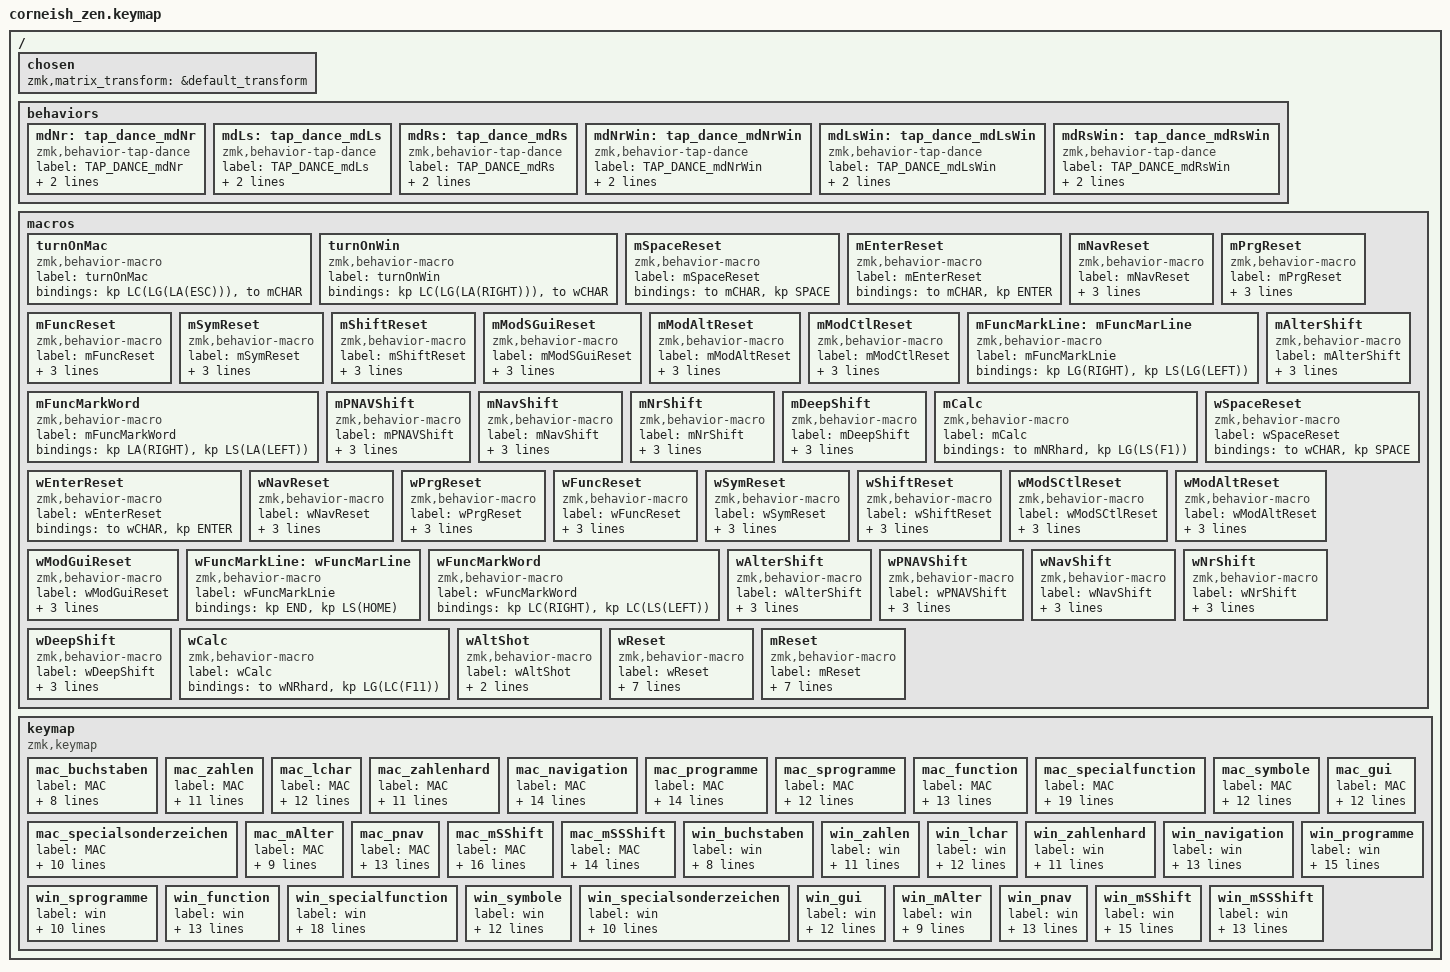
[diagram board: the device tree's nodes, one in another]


#include <behaviors.dtsi>
#include <dt-bindings/zmk/keys.h>
#include <dt-bindings/zmk/bt.h>


// ------- MAC -------------------

#define mCHAR 0
#define mNR 1
#define mLCHAR 2
#define mNRhard 3

#define mNAV 4

#define mPRG 5
#define mSPRG 6

#define mFUNC 7
#define mSFUNC 8

#define mSYM 9
#define mSSYM 10

#define mGUI 11

#define mAlter 12
#define mPNAV 13

#define mSShift 14
#define mSSShift 15


// ------- WIN -------------------


#define wCHAR 16
#define wNR 17
#define wLCHAR 18
#define wNRhard 19

#define wNAV 20

#define wPRG 21
#define wSPRG 22

#define wFUNC 23
#define wSFUNC 24

#define wSYM 25
#define wSSYM 26

#define wGUI 27

#define wAlter 28
#define wPNAV 29

#define wSShift 30
#define wSSShift 31




/ {
    chosen {
    	zmk,matrix_transform = &default_transform;
    };
};




/ {

    behaviors {

	

		// ------------------------- MAC ---------------------
	

        mdNr: tap_dance_mdNr {
            compatible = "zmk,behavior-tap-dance";
            label = "TAP_DANCE_mdNr";
            #binding-cells = <0>;
            tapping-term-ms = <200>;
            bindings = <&to mNR>, <&to mNRhard>;
        };


		mdLs: tap_dance_mdLs {
            compatible = "zmk,behavior-tap-dance";
            label = "TAP_DANCE_mdLs";
            #binding-cells = <0>;
            tapping-term-ms = <1000>;
            bindings = <&sl mLCHAR>, <&to mLCHAR>;
        };
		mdRs: tap_dance_mdRs {
            compatible = "zmk,behavior-tap-dance";
            label = "TAP_DANCE_mdRs";
            #binding-cells = <0>;
            tapping-term-ms = <1000>;
            bindings = <&sl mLCHAR>, <&to mLCHAR>;
        };



		// ------------------------- WiN ---------------------

		mdNrWin: tap_dance_mdNrWin {
            compatible = "zmk,behavior-tap-dance";
            label = "TAP_DANCE_mdNrWin";
            #binding-cells = <0>;
            tapping-term-ms = <200>;
            bindings = <&to wNR>, <&to wNRhard>;
        };

		mdLsWin: tap_dance_mdLsWin {
            compatible = "zmk,behavior-tap-dance";
            label = "TAP_DANCE_mdLsWin";
            #binding-cells = <0>;
            tapping-term-ms = <1000>;
            bindings = <&sl wLCHAR>, <&to wLCHAR>;
        };
		mdRsWin: tap_dance_mdRsWin {
            compatible = "zmk,behavior-tap-dance";
            label = "TAP_DANCE_mdRsWin";
            #binding-cells = <0>;
            tapping-term-ms = <1000>;
            bindings = <&sl wLCHAR>, <&to wLCHAR>;
        };

    };

	
	 macros {

		// OS Switch

		turnOnMac: turnOnMac {
            label = "turnOnMac";
            compatible = "zmk,behavior-macro";
            #binding-cells = <0>;
            bindings
                = <&kp LC(LG(LA(ESC)))>
				, <&to mCHAR>
                ;
    	};

		turnOnWin: turnOnWin {
            label = "turnOnWin";
            compatible = "zmk,behavior-macro";
            #binding-cells = <0>;
            bindings
                = <&kp LC(LG(LA(RIGHT)))>
                , <&to wCHAR>
                ;
    	};



		
		// ------------------------- MAC ---------------------

        mSpaceReset: mSpaceReset {
            label = "mSpaceReset";
            compatible = "zmk,behavior-macro";
            #binding-cells = <0>;
            bindings
                = <&to mCHAR>
                , <&kp SPACE>
                ;
    	};
		mEnterReset: mEnterReset {
            label = "mEnterReset";
            compatible = "zmk,behavior-macro";
            #binding-cells = <0>;
            bindings
                = <&to mCHAR>
                , <&kp ENTER>
                ;
    	};
		mNavReset: mNavReset {
            label = "mNavReset";
            compatible = "zmk,behavior-macro";
            #binding-cells = <0>;
            bindings
                = <&to mCHAR>
                , <&macro_press &sl mNAV>
    			, <&macro_pause_for_release>
				, <&macro_release &sl mNAV>
                ;
    	};
		mPrgReset: mPrgReset {
            label = "mPrgReset";
            compatible = "zmk,behavior-macro";
            #binding-cells = <0>;
            bindings
                = <&to mCHAR>
                , <&macro_press &sl mPRG>
    			, <&macro_pause_for_release>
				, <&macro_release &sl mPRG>
                ;
    	};
		mFuncReset: mFuncReset {
            label = "mFuncReset";
            compatible = "zmk,behavior-macro";
            #binding-cells = <0>;
            bindings
                = <&to mCHAR>
                , <&macro_press &sl mFUNC>
    			, <&macro_pause_for_release>
				, <&macro_release &sl mFUNC>
                ;
    	};
		mSymReset: mSymReset {
            label = "mSymReset";
            compatible = "zmk,behavior-macro";
            #binding-cells = <0>;
            bindings
                = <&to mCHAR>
                , <&macro_press &sl mSYM>
    			, <&macro_pause_for_release>
				, <&macro_release &sl mSYM>
                ;
    	};

		mShiftReset: mShiftReset {
            label = "mShiftReset";
            compatible = "zmk,behavior-macro";
            #binding-cells = <0>;
            bindings
                = <&to mCHAR>
                , <&macro_press &sl mLCHAR>
    			, <&macro_pause_for_release>
				, <&macro_release &sl mLCHAR>
                ;
    	};


		mModSGuiReset: mModSGuiReset {
            label = "mModSGuiReset";
            compatible = "zmk,behavior-macro";
            #binding-cells = <0>;
            bindings
                = <&to mCHAR>
                , <&macro_press &sk LS(LGUI)>
    			, <&macro_pause_for_release>
				, <&macro_release &sk LS(LGUI)>
                ;
    	};


		mModAltReset: mModAltReset {
            label = "mModAltReset";
            compatible = "zmk,behavior-macro";
            #binding-cells = <0>;
            bindings
                = <&to mCHAR>
                , <&macro_press &sk LALT>
    			, <&macro_pause_for_release>
				, <&macro_release &sk LALT>
                ;
    	};

		mModCtlReset: mModCtlReset {
            label = "mModCtlReset";
            compatible = "zmk,behavior-macro";
            #binding-cells = <0>;
            bindings
                = <&to mCHAR>
                , <&macro_press &sk LCTL>
    			, <&macro_pause_for_release>
				, <&macro_release &sk LCTL>
                ;
    	};





		mFuncMarkLine: mFuncMarLine {
            label = "mFuncMarkLnie";
            compatible = "zmk,behavior-macro";
            #binding-cells = <0>;
            bindings
                = <&kp LG(RIGHT)>
				, <&kp LS(LG(LEFT))>
                ;
    	};

		mFuncMarkWord: mFuncMarkWord {
            label = "mFuncMarkWord";
            compatible = "zmk,behavior-macro";
            #binding-cells = <0>;
            bindings
                = <&kp LA(RIGHT)>
				, <&kp LS(LA(LEFT))>
                ;
    	};



		mAlterShift: mAlterShift {
            label = "mAlterShift";
            compatible = "zmk,behavior-macro";
            #binding-cells = <0>;
            bindings
                = <&to mCHAR>
                , <&macro_press &sl mAlter>
    			, <&macro_pause_for_release>
				, <&macro_release &sl mAlter>
                ;
    	};

		mPNAVShift: mPNAVShift {
            label = "mPNAVShift";
            compatible = "zmk,behavior-macro";
            #binding-cells = <0>;
            bindings
                = <&to mCHAR>
                , <&macro_press &sl mPNAV>
    			, <&macro_pause_for_release>
				, <&macro_release &sl mPNAV>
                ;
    	};

		mNavShift: mNavShift {
            label = "mNavShift";
            compatible = "zmk,behavior-macro";
            #binding-cells = <0>;
            bindings
                = <&to mCHAR>
                , <&macro_press &sl mNAV>
    			, <&macro_pause_for_release>
				, <&macro_release &sl mNAV>
				;
    	};

		mNrShift: mNrShift {
            label = "mNrShift";
            compatible = "zmk,behavior-macro";
            #binding-cells = <0>;
            bindings
                = <&to mCHAR>
                , <&macro_press &sl mNR>
    			, <&macro_pause_for_release>
				, <&macro_release &sl mNR>
				;
    	};

		mDeepShift: mDeepShift {
            label = "mDeepShift";
            compatible = "zmk,behavior-macro";
            #binding-cells = <0>;
            bindings
                = <&to mCHAR>
                , <&macro_press &sl mPNAV>
    			, <&macro_pause_for_release>
				, <&macro_release &sl mPNAV>
				;
    	};

		mCalc: mCalc {
            label = "mCalc";
            compatible = "zmk,behavior-macro";
            #binding-cells = <0>;
            bindings
                = <&to mNRhard>
            	, <&kp LG(LS(F1))>
                ;
    	};





		// ------------------------- WiN ---------------------

        wSpaceReset: wSpaceReset {
            label = "wSpaceReset";
            compatible = "zmk,behavior-macro";
            #binding-cells = <0>;
            bindings
                = <&to wCHAR>
                , <&kp SPACE>
                ;
    	};
		wEnterReset: wEnterReset {
            label = "wEnterReset";
            compatible = "zmk,behavior-macro";
            #binding-cells = <0>;
            bindings
                = <&to wCHAR>
                , <&kp ENTER>
                ;
    	};
		wNavReset: wNavReset {
            label = "wNavReset";
            compatible = "zmk,behavior-macro";
            #binding-cells = <0>;
            bindings
                = <&to wCHAR>
                , <&macro_press &sl wNAV>
    			, <&macro_pause_for_release>
				, <&macro_release &sl wNAV>
                ;
    	};
		wPrgReset: wPrgReset {
            label = "wPrgReset";
            compatible = "zmk,behavior-macro";
            #binding-cells = <0>;
            bindings
                = <&to wCHAR>
                , <&macro_press &sl wPRG>
    			, <&macro_pause_for_release>
				, <&macro_release &sl wPRG>
                ;
    	};
		wFuncReset: wFuncReset {
            label = "wFuncReset";
            compatible = "zmk,behavior-macro";
            #binding-cells = <0>;
            bindings
                = <&to wCHAR>
                , <&macro_press &sl wFUNC>
    			, <&macro_pause_for_release>
				, <&macro_release &sl wFUNC>
                ;
    	};
		wSymReset: wSymReset {
            label = "wSymReset";
            compatible = "zmk,behavior-macro";
            #binding-cells = <0>;
            bindings
                = <&to wCHAR>
                , <&macro_press &sl wSYM>
    			, <&macro_pause_for_release>
				, <&macro_release &sl wSYM>
                ;
    	};

		wShiftReset: wShiftReset {
            label = "wShiftReset";
            compatible = "zmk,behavior-macro";
            #binding-cells = <0>;
            bindings
                = <&to wCHAR>
                , <&macro_press &sl wLCHAR>
    			, <&macro_pause_for_release>
				, <&macro_release &sl wLCHAR>
                ;
    	};



		wModSCtlReset: wModSCtlReset {
            label = "wModSCtlReset";
            compatible = "zmk,behavior-macro";
            #binding-cells = <0>;
            bindings
                = <&to wCHAR>
                , <&macro_press &sk LS(LCTL)>
    			, <&macro_pause_for_release>
				, <&macro_release &sk LS(LCTL)>
                ;
    	};


		wModAltReset: wModAltReset {
            label = "wModAltReset";
            compatible = "zmk,behavior-macro";
            #binding-cells = <0>;
            bindings
                = <&to wCHAR>
                , <&macro_press &sk LALT>
    			, <&macro_pause_for_release>
				, <&macro_release &sk LALT>
                ;
    	};

		wModGuiReset: wModGuiReset {
            label = "wModGuiReset";
            compatible = "zmk,behavior-macro";
            #binding-cells = <0>;
            bindings
                = <&to wCHAR>
                , <&macro_press &sk LGUI>
    			, <&macro_pause_for_release>
				, <&macro_release &sk LGUI>
                ;
    	};



		wFuncMarkLine: wFuncMarLine {
            label = "wFuncMarkLnie";
            compatible = "zmk,behavior-macro";
            #binding-cells = <0>;
            bindings
                = <&kp END>
				, <&kp LS(HOME)>
                ;
    	};

		wFuncMarkWord: wFuncMarkWord {
            label = "wFuncMarkWord";
            compatible = "zmk,behavior-macro";
            #binding-cells = <0>;
            bindings
                = <&kp LC(RIGHT)>
				, <&kp LC(LS(LEFT))>
                ;
    	};



		wAlterShift: wAlterShift {
            label = "wAlterShift";
            compatible = "zmk,behavior-macro";
            #binding-cells = <0>;
            bindings
                = <&to wCHAR>
                , <&macro_press &sl wAlter>
    			, <&macro_pause_for_release>
				, <&macro_release &sl wAlter>
                ;
    	};

		wPNAVShift: wPNAVShift {
            label = "wPNAVShift";
            compatible = "zmk,behavior-macro";
            #binding-cells = <0>;
            bindings
                = <&to wCHAR>
                , <&macro_press &sl wPNAV>
    			, <&macro_pause_for_release>
				, <&macro_release &sl wPNAV>
                ;
    	};

		wNavShift: wNavShift {
            label = "wNavShift";
            compatible = "zmk,behavior-macro";
            #binding-cells = <0>;
            bindings
                = <&to wCHAR>
                , <&macro_press &sl wNAV>
    			, <&macro_pause_for_release>
				, <&macro_release &sl wNAV>
				;
    	};


		wNrShift: wNrShift {
            label = "wNrShift";
            compatible = "zmk,behavior-macro";
            #binding-cells = <0>;
            bindings
                = <&to wCHAR>
                , <&macro_press &sl wNR>
    			, <&macro_pause_for_release>
				, <&macro_release &sl wNR>
				;
    	};

		wDeepShift: wDeepShift {
            label = "wDeepShift";
            compatible = "zmk,behavior-macro";
            #binding-cells = <0>;
            bindings
                = <&to wCHAR>
                , <&macro_press &sl wPNAV>
    			, <&macro_pause_for_release>
				, <&macro_release &sl wPNAV>
				;
    	};

		wCalc: wCalc {
            label = "wCalc";
            compatible = "zmk,behavior-macro";
            #binding-cells = <0>;
            bindings
                = <&to wNRhard>
            	, <&kp LG(LC(F11))>
                ;
    	};

		wAltShot: wAltShot {
            label = "wAltShot";
            compatible = "zmk,behavior-macro";
            #binding-cells = <0>;
            bindings
                = <&macro_press &kp LALT>
				, <&macro_release  &kp LALT>
                ;
    	};


		// Reset

		wReset: wReset {
            label = "wReset";
            compatible = "zmk,behavior-macro";
            #binding-cells = <0>;
            bindings
				= <&to wCHAR>
				, <&kp LC(LG(LA(NUBS)))>
				, <&macro_release &kp LALT>
				, <&macro_release &kp RALT>
				, <&macro_release &kp LCTL>
				, <&macro_release &kp RCTL>
				, <&macro_release &kp LSFT>
				, <&macro_release &kp RSFT>
				, <&macro_release &kp LGUI>
				, <&macro_release &kp RGUI>

                ; 
    	};

		mReset: mReset {
            label = "mReset";
            compatible = "zmk,behavior-macro";
            #binding-cells = <0>;
            bindings
				= <&to mCHAR>
				, <&kp LC(LG(LA(NUBS)))>
				, <&macro_release &kp LALT>
				, <&macro_release &kp RALT>
				, <&macro_release &kp LCTL>
				, <&macro_release &kp RCTL>
				, <&macro_release &kp LSFT>
				, <&macro_release &kp RSFT>
				, <&macro_release &kp LGUI>
				, <&macro_release &kp RGUI>
                ; 
    	};




	};





	keymap
	{	
		compatible = "zmk,keymap";



		// ----------------------------------------------------------------------------------------------|
		// 											MAC			
		// ----------------------------------------------------------------------------------------------|


		// -----------------------------------------------------|
		// Layer 0 - mChar = 	  Buchstaben					|
		// -----------------------------------------------------|
	
		mac_buchstaben
		{
			label = "MAC";

			bindings = <

				// ----------------------------------------

				&kp ESC
				&kp J 
				&kp D	 
				&kp U
				&kp A
				&kp X

				&kp P
				&kp H
				&kp L
				&kp M
				&kp W
				&kp BSPC

				// ----------------------------------------
	
				&sl mSShift
				&kp C
				&kp T
				&kp I
				&kp E
				&kp O

				&kp B
				&kp N
				&kp R
				&kp S
				&kp G
				&kp RET

				// ----------------------------------------
	
				&mdLs
				&kp F
				&kp V
				&kp MINUS
				&kp Y
				&kp Q

				&kp Z
				&kp SEMI
				&kp LBKT
				&kp SQT
				&kp K
				&mdRs

				// ----------------------------------------

				&sl mSYM
				&kp SPACE
				&sl mFUNC
				&sl mPRG
				&sl mNAV
				&mdNr

				// ----------------------------------------
			>;
		};



		// -----------------------------------------------------|
		// Layer 1 - mNR = 	  Zahlen 							|
		// -----------------------------------------------------|

		mac_zahlen
		{
			label = "MAC";

			bindings = <

				// ----------------------------------------

				&kp ESC	
				&kp RBKT  				// +
				&kp NUBS				// Spitze
				&kp LS(NUBS)			// Spitze
				&kp GRAVE				// ^
				&kp X
				
				&kp LS(NUHS)			// '
				&kp LS(DOT)				// :
				&kp LS(COMMA)			// ;
				&kp M
				&kp LS(RBKT)			// *				
				&kp BACKSPACE

				// ----------------------------------------

				&sl mSShift
				&kp N1				
				&kp N2				
				&kp N3				
				&kp N4					
				&kp N5		

				&kp N6				
				&kp N7				
				&kp N8			
				&kp N9				
				&kp N0				
				&mEnterReset 

				// ----------------------------------------

				&mShiftReset
				&kp LS(N7)				// /
				&kp LS(LA(N7))			// backlslash
				&kp LS(N5)				// %
				&kp LA(E)				// €
				&kp GRAVE				// ^

				&kp LS(N0)				// =
				&kp DOT					// .
				&kp COMMA				// ,
				&kp LS(SLASH)			// _
				&kp SLASH 				// -
				&mShiftReset

				// ----------------------------------------
		
				&mSymReset
				&mSpaceReset 
				&mFuncReset
				&mPrgReset
				&mNavReset
				&none
			>;		
		};



		// -----------------------------------------------------|
		// Layer 2 - mLCHAR = 	  Buchstaben Lock				|
		// -----------------------------------------------------|
	
		mac_lchar
		{
			label = "MAC";

			bindings = <

				// ----------------------------------------

				&kp ESC
				&kp LS(J) 
				&kp LS(D)	 
				&kp LS(U)
				&kp LS(A)
				&kp LS(X)

				&kp LS(P)
				&kp LS(H)
				&kp LS(L)
				&kp LS(M)
				&kp LS(W)
				&kp LS(BSPC)

				// ----------------------------------------
	
				&sl mSShift
				&kp LS(C)
				&kp LS(T)
				&kp LS(I)
				&kp LS(E)
				&kp LS(O)
			
				&kp LS(B)
				&kp LS(N)
				&kp LS(R)
				&kp LS(S)
				&kp LS(G)
				&mEnterReset

				// ----------------------------------------

				&mShiftReset
				&kp LS(F)
				&kp LS(V)
				&kp LS(MINUS)
				&kp LS(Y)
				&kp LS(Q)

				&kp LS(Z)
				&kp LS(SEMI)
				&kp LS(LBKT)
				&kp LS(SQT)
				&kp LS(K)
				&mShiftReset						

				// ----------------------------------------

				&sl mSYM
				&mSpaceReset 
				&mFuncReset
				&mPrgReset
				&mNavReset
				&mdNr

				// ----------------------------------------
			>;
		};



		// -----------------------------------------------------|
		// Layer 3 - mNRhard = 	  Zahlen Hard Lock				|
		// -----------------------------------------------------|

		mac_zahlenhard
		{
			label = "MAC";

			bindings = <

				// ----------------------------------------

				&kp ESC	
				&kp RBKT  				// +
				&kp NUBS				// Spitze
				&kp LS(NUBS)			// Spitze
				&kp GRAVE				// ^
				&kp X
				
				&kp LS(NUHS)			// '
				&kp LS(DOT)				// :
				&kp LS(COMMA)			// ;
				&kp M
				&kp LS(RBKT)			// *	
				&kp BSPC

				// ----------------------------------------

				&sl mSShift
				&kp N1				
				&kp N2				
				&kp N3				
				&kp N4					
				&kp N5		

				&kp N6				
				&kp N7				
				&kp N8				
				&kp N9				
				&kp N0				
				&kp ENTER 

				// ----------------------------------------

				&mShiftReset
				&kp LS(N7)				// /
				&kp LS(LA(N7))			// backlslash
				&kp LS(N5)				// %
				&kp LA(E)				// €
				&kp GRAVE				// ^

				&kp LS(N0)				// =
				&kp DOT					// .
				&kp COMMA				// ,
				&kp LS(SLASH)			// _
				&kp SLASH 				// -
				&mShiftReset

				// ----------------------------------------
		
				&sl mSYM
				&kp SPACE
				&sl mFUNC
				&sl mPRG
				&sl mNAV
				&mdNr
			>;		
		};





		// -----------------------------------------------------|
		// Layer = 4 - mNAV - Navigation						|
		// -----------------------------------------------------|

		mac_navigation
		{		
			label = "MAC";

			bindings = <

				// ----------------------------------------

				&kp ESC						// -
				&kp LG(UP)					// @Home Sprung
				&kp LS(TAB)
				&kp UP						// @Up
				&kp TAB
				&kp LG(LA(F16))	
		
				&kp LG(LA(F17))				 
				&kp LC(GRAVE)			
				&kp PG_UP
				&kp LC(EQUAL)
				&kp LG(LS(UP))			
				&kp DEL					// -

				// ----------------------------------------

				&kp LC(COMMA)				 	// 
				&kp LG(DOWN)				// @End Sprung
				&kp LEFT 					// @Left
				&kp DOWN					// @Down
				&kp RIGHT 					// @Right
				&kp LC(DOT)			 	// 

				&kp LC(LS(F10))		
				&kp LS(LC(TAB))				 
				&kp PG_DN
				&kp LC(TAB)				 	
				&kp LG(LS(DOWN))	
				&kp ENTER					
				
				// ----------------------------------------

				&kp LCTRL
				&kp LG(LEFT)				// @Home 
				&kp LA(LEFT)				// @Wort Sprung
				&kp LA(RIGHT)				// @Wort Sprung
				&kp LG(RIGHT)				// @End  
				&kp LG(LA(F18))	

				&kp LG(LA(F19))	 	
				&kp LG(LS(LEFT))				// @Home 
				&kp LA(LS(LEFT))				// @Wort Sprung
				&kp LA(LS(RIGHT))				// @Wort Sprung
				&kp LG(LS(RIGHT))				// @End  
				&kp LSHFT

				// ----------------------------------------

				&sl mSYM
				&kp SPACE				
				&sl mFUNC
				&sl mPRG
				&mReset
				&mdNr

				// ----------------------------------------							
			>;
		};





		// -----------------------------------------------------|
		// Layer 6 - mPRG =	Programme							|
		// -----------------------------------------------------|


		mac_programme
		{
			label = "MAC";

			bindings = <

				// ----------------------------------------

				&kp LG(H)
				&kp LG(LS(N1))				// 11
				&kp LG(LS(N2))				// 12
				&kp LG(LS(N3))				// 13
				&kp LG(LS(N4))				// 14
				&kp LG(LS(N5))				// 15

				&kp LG(LS(N6))				// 16
				&kp LG(LS(N7))				// 17
				&kp LG(LS(N8))				// 18
				&kp LG(LS(N9))				// 19
				&kp LG(LS(N0))				// 20
				&kp LG(Q)

				// ----------------------------------------

				&kp LG(TAB)
				&kp LG(LA(N1))				// 1
				&kp LG(LA(N2))				// 2
				&kp LG(LA(N3))				// 3
				&kp LG(LA(N4))				// 4
				&kp LG(LA(N5))				// 5

				&kp LG(LA(N6))				// 6
				&kp LG(LA(N7))				// 7
				&kp LG(LA(N8))				// 8
				&kp LG(LA(N9))				// 9
				&kp LG(LA(N0))				// 0
				&kp LG(LA(LC(ENTER)))

				// ----------------------------------------

				&kp LG(LS(F2))
				&kp LC(LA(N1))			// 21 			
				&kp LC(LA(N2))			// 22
				&kp LC(LA(N3))			// 23
				&kp LC(LA(N4))			// 24
				&kp LC(LA(N5))			// 25
	
				&kp LC(LA(N6))			// 26
				&kp LC(LA(N7))			// 27
				&kp LC(LA(N8))			// 28
				&kp LC(LA(N9))			// 29
				&kp LC(LA(N0))			// 30
				&kp LG(LS(F3))
		
				// ----------------------------------------

				&none
				&none
				&none
				&sl mSPRG					// deep						
				&mNavShift
				&mCalc

				// ----------------------------------------

			>;
		};
		


		// -----------------------------------------------------|
		// Layer 7 - mSPRG =	Spezial Prgramme				|
		// -----------------------------------------------------|


		mac_sprogramme
		{

			label = "MAC";

			bindings = <

				// ----------------------------------------

				&kp LG(LA(H))			// #OPEN
				&kp LA(F1)				//
				&kp LA(F2)				//
				&kp LA(F3)				//
				&kp LA(F4)				//
				&kp LA(F5)				//

				&kp LG(F1)				//
				&kp LG(F2)				//
				&kp LG(F3)				//
				&kp LG(F4)				//
				&kp LG(F5)				//
				&kp LG(LA(ESC))			// #OPEN
		
				// ----------------------------------------

				&kp LG(LS(TAB))			// #OPEN
				&kp LA(F6)				//
				&kp LA(F7)				//
				&kp LA(F8)				//
				&kp LA(F9)				//
				&kp LA(F9)				//

				&kp LC(F6)				//
				&kp LC(F7)				//
				&kp LC(F8)				//
				&kp LC(F9)				//
				&kp LC(F10)				//
				&kp LG(LS(F4))

				// ----------------------------------------

				&kp LG(LS(F5))
				&kp LA(F11)				//
				&kp LA(F12)				//
				&kp LA(F13)				//
				&kp LA(F14)				//
				&kp LA(F15)				//

				&kp LG(F11)				//
				&kp LG(F12)				//
				&kp LG(F13)				//
				&kp LG(F14)				//
				&kp LG(F15)				//
				&kp LG(LS(F6))
		
				// ----------------------------------------

				&none						//
				&none						//
				&none
				&trans						// 
				&mNavShift
				&none						// 

				// ----------------------------------------

			>;
		};
					


		// -----------------------------------------------------|
		// Layer 8 - mFUNC =	Funktionen						|
		// -----------------------------------------------------|

		mac_function
		{
			label = "MAC";

			bindings = <

				// ----------------------------------------
	
				&kp LG(LS(F7))
				&kp LC(LA(F1))	
				&kp LC(LA(F2))	
				&kp LC(LA(F3))	
				&kp LC(LA(F4))	
				&kp LC(LA(F5))	

				&kp LC(LA(F6))	
				&kp LC(LA(F7))	
				&kp LC(LA(F8))	
				&kp LC(LA(F9))	
				&kp LC(LA(F10))	
				&kp LG(W)				
				
				// ----------------------------------------

				&kp LG(LS(F8))
				&kp LG(A)
				&kp LG(DEL)	
				&kp LG(INSERT)	
				&kp LG(C)			
				&kp LG(X)

				&kp LG(LA(V))
				&kp LG(V)
				&kp LG(LA(V))	
				&kp LG(LA(I))	
				&kp LG(LA(D))	
				&kp ENTER

				// ----------------------------------------

				&kp LG(LS(F9))
				&kp LG(S)
				&kp LG(Y)
				&kp LG(LS(Y))
				&kp LG(O)
				&kp LG(D)	

				&kp LG(P)	
				&kp LG(LA(F))	
				&kp LG(LA(N))	
				&kp LG(LA(M))	
				&kp LG(F)	
				&kp LG(T)
				
				// ----------------------------------------

				&mModAltReset				//
				&sl mGUI					//
				&sl mSFUNC					// deep
				&none
				&mNavShift					//
				&none						//

				// ----------------------------------------
			>;
		};



		// -----------------------------------------------------|
		// Layer 9 - mSFUNC =	Spezial Funktionen				|
		// -----------------------------------------------------|

		mac_specialfunction
		{
			label = "MAC";

			bindings = <

			// ----------------------------------------
	
				&kp LG(LS(F10))			
				&kp LC(LA(LS(F1)))	
				&kp LC(LA(LS(F2)))	
				&kp LC(LA(LS(F3)))	
				&kp LC(LA(LS(F4)))	
				&kp LC(LA(LS(F5)))	

				&kp LC(LA(LS(F6)))	
				&kp LC(LA(LS(F7)))	
				&kp LC(LA(LS(F8)))	
				&kp LC(LA(LS(F9)))
				&kp LC(LA(LS(F10)))	
				&kp LS(LG(W))
				
				// ----------------------------------------

				&kp LG(LS(F11))		
				&kp LG(LS(A))
				&kp LG(LS(DEL))	
				&kp LG(LS(INSERT))	
				&kp LG(LS(C))			
				&kp LG(LS(X))

				&kp LG(LA(LS(V)))
				&kp LG(LS(V))
				&kp LG(LA(LS(V)))	
				&kp LG(LA(LS(I)))	
				&kp LG(LA(LS(D)))	
				&kp LG(LS(ENTER))	

				// ----------------------------------------

				&kp LG(LS(F12))		
				&kp LG(LS(S))
				&kp LG(LA(LS(Y)))
				&kp LG(LA(LS(Y)))
				&kp LG(LS(O))
				&kp LG(LS(D))	

				&kp LG(LS(P))	
				&kp LG(LA(LS(F)))	
				&kp LG(LA(LS(N)))	
				&kp LG(LA(LS(M)))	
				&kp LG(LS(F))	
				&kp LS(LG(LS(T)))
				
				// ----------------------------------------

				&mModCtlReset
				&mModSGuiReset
				&trans						// 
				&none
				&mNavShift						//
				&none						//

				// ----------------------------------------       
			>;
		};



		// -----------------------------------------------------|
		// Layer 10 - mSYM =	Symoble							|
		// -----------------------------------------------------|

		mac_symbole
		{
			label = "MAC";

			bindings = <

				// ----------------------------------------
				
				&kp ESC
				&kp RBKT  				// +
				&kp NUBS				// Spitze
				&kp LS(NUBS)			// Spitze
				&kp GRAVE				// ^
				&kp X
				
				&kp LS(NUHS)			// '
				&kp LS(DOT)				// :
				&kp LS(COMMA)			// ;
				&kp M
				&kp LS(RBKT)			// *	
				&kp BACKSPACE			// Backspace

				// ----------------------------------------

				&kp LGUI
				&kp LA(L)				// @
				&kp LA(N7)				// grader strich
				&kp LS(N6)				// &
				&kp NUHS				// #
				&kp LS(N3)				// §

				&kp LS(N2)				// "
				&kp LS(N1)				// !
				&kp LS(N8)				// Runde
				&kp LS(N9)				// Runde
				&kp LS(MINUS)			// ?
				&kp ENTER

				// ----------------------------------------

				&kp LSHIFT				//
				&kp LS(N7)				// /
				&kp LS(LA(N7))			// backlslash
				&kp LS(N5)				// %
				&kp LA(E)				// €
				&kp GRAVE				// ^

				&kp LS(N0)				// =
				&kp DOT					// .
				&kp COMMA				// ,
				&kp LS(SLASH)			// _
				&kp SLASH 				// -
				&kp LG(LC(SPACE))   	// @Sonderzeichen
		
				// ----------------------------------------

				&sl mSSYM				// deep
				&none		 			//
				&none					// 
				&none					//
				&mNavShift				//
				&none					//

				// ----------------------------------------
			>;
		};


		// -----------------------------------------------------|
		// Layer 11 - mSSYM =	Special Symbole					|
		// -----------------------------------------------------|

		mac_specialsonderzeichen
		{
			label = "MAC";

			bindings = <

				// ----------------------------------------

				&kp ESC
				&trans					//
				&trans 					// 
				&trans					//
				&trans					//
				&trans					//

				&trans					//
				&trans
				&trans					//
				&kp RA(M)				// 
				&trans					//
				&kp BACKSPACE			// 

				// ----------------------------------------

				&kp LCTL
				&trans					//
				&kp LS(GRAVE)			// Grad
				&trans					//
				&trans					//
				&trans					//

				&trans					//
				&trans					//
				&kp LA(N5)				// Eckige
				&kp LA(N6)				// Eckige
				&trans					//
				&kp ENTER

				// ----------------------------------------

				&kp LALT
				&kp LS(LA(N7))			// 
				&trans
				&trans
				&kp LS(N4) 				// $
				&trans					//

				&kp LA(N)				// ~
				&trans
				&kp LA(N8)				// Geschweift
				&kp LA(N9)				// Geschweift
				&kp LS(SLASH)			// _
				&kp LG(LC(SPACE))   	// @Sonderzeichen

				// ----------------------------------------

				&trans					//
				&none
				&none					// 
				&none					//
				&mNavShift				// 
				&none					//

				// ----------------------------------------
			>;
		};	




		// -----------------------------------------------------|
		// Layer 12 - mGUI =	GUI								|
		// -----------------------------------------------------|

		mac_gui
		{
			label = "MAC";

			bindings = <

				// ----------------------------------------

				&kp LG(ESC)					// 
				&kp LG(J)					//
				&kp LG(D)					//
				&kp LG(U)					//
				&kp LG(A)					//
				&kp LG(X)					//

				&kp LG(P)					//
				&kp LG(H)					//
				&kp LG(L) 					//
				&kp LG(M)					//
				&kp LG(W) 					//
				&kp LG(BACKSPACE)			//

				// ----------------------------------------
		
				&kp LG(DEL)					//
				&kp LG(C)					//
				&kp LG(T)					//
				&kp LG(I)					//
				&kp LG(E)					//
				&kp LG(O)					//

				&kp LG(B)					//
				&kp LG(N)					//
				&kp LG(R)					//
				&kp LG(S)					//
				&kp LG(G)					//
				&kp LG(ENTER)				// 

				// ----------------------------------------

				&kp LSHIFT
				&kp LG(F)					//
				&kp LG(V)					//
				&kp LG(MINUS)				//
				&kp LG(Y)					//
				&kp LG(Q)					//

				&kp LG(Z)					//
				&kp LG(SEMICOLON)			//
				&kp LG(LEFT_BRACKET)		//
				&kp LG(SINGLE_QUOTE)		//
				&kp LG(K) 					//
				&kp LSHIFT

				// ----------------------------------------
		
				&none						//
				&trans
				&none						// 
				&none						//
				&mNavShift						//
				&none						// 

				// ----------------------------------------
			>;
		};




		// -----------------------------------------------------|
		// Layer 16 - mAlter =	Alterantive						|
		// -----------------------------------------------------|

		mac_mAlter
		{
			label = "MAC";

			bindings = <

				// ----------------------------------------

				&none
				&kp F1
				&kp F2
				&kp F3
				&kp F4
				&kp F5

				&kp F6
				&kp F7
				&kp F8
				&kp F9
				&kp F10
				&none

				// ----------------------------------------
		
				&none
				&kp LG(N1)					// 11
				&kp LG(N2)					// 12
				&kp LG(N3)					// 13
				&kp LG(N4)					// 14
				&kp LG(N5)					// 15

				&kp LG(N6)					// 16
				&kp LG(N7)					// 17
				&kp LG(N8)					// 18
				&kp LG(N9)					// 19
				&kp LG(N0)					// 20
				&none

				// ----------------------------------------

				&none
				&kp F11
				&kp F12
				&kp F13
				&kp F14
				&kp F15

				&kp LC(LS(F1))
				&kp LC(LS(F2))
				&kp LC(LS(F3))
				&kp LC(LS(F4))
				&kp LC(LS(F5))
				&none

				// ----------------------------------------
		
				&none						//
				&trans
				&none						// 
				&none						//
				&mNavShift						//
				&none						// 

				// ----------------------------------------
			>;
		};






		// -----------------------------------------------------|
		// Layer 17 - mPNAV =	Programm NAV					|
		// -----------------------------------------------------|

		mac_pnav
		{
			label = "MAC";

			bindings = <

				// ----------------------------------------

				&kp LG(LA(ENTER))			// 
				&none						//
				&kp LG(LA(LS(LEFT)))		 
				&kp LG(LA(UP))				// 
				&kp LG(LA(LS(RIGHT)))			
				&none						// 

				&kp LA(LG(F11)) 					
				&kp LA(LG(F12))					
				&kp LA(LG(F13)) 					
				&kp LA(LG(F14))					
				&kp LA(LG(F15)) 
				&kp BACKSPACE				//

				// ----------------------------------------
		
				&none						//
				&none						//
				&kp LG(LA(LEFT))			// 
				&kp LG(LA(DOWN))			// 
				&kp LG(LA(RIGHT))			// 
				&none						// 

				&kp LA(LG(F1)) 					
				&kp LA(LG(F2))					
				&kp LA(LG(F3)) 					
				&kp LA(LG(F4))					
				&kp LA(LG(F5)) 
				&none						//

				// ----------------------------------------

				&none						//
				&none						//
				&none						// 
				&none						//
				&none						// 
				&none						// 

				&kp LA(LG(F6)) 					
				&kp LA(LG(F7))					
				&kp LA(LG(F8)) 					
				&kp LA(LG(F9))					
				&kp LA(LG(F10)) 
				&none						//

				// ----------------------------------------
		
				&none						//
				&none
				&none						// 
				&none						//
				&mNavShift
				&none						// 

				// ----------------------------------------
			>;
		};





		// -----------------------------------------------------|
		// Layer 19 - mSideShift =	Side Shift					|
		// -----------------------------------------------------|

		mac_mSShift
		{
			label = "MAC";

			bindings = <

				// ----------------------------------------

				&kp ESC						// 
				&bt BT_SEL 0
				&bt BT_SEL 1
				&bt BT_SEL 2
				&bt BT_SEL 3
				&bt BT_CLR

				&kp LC(LA(LG(F11))) 					
				&kp LC(LA(LG(F12))) 
				&kp LC(LA(LG(F13))) 
				&kp LC(LA(LG(F14))) 
				&kp LC(LA(LG(F15))) 
				&kp BACKSPACE				//

				// ----------------------------------------
		
				&mDeepShift
				&none	
				&none
				&none
				&kp LG(LA(LC(SPACE)))					
				&none

				&kp LC(LA(LG(F1))) 					
				&kp LC(LA(LG(F2))) 
				&kp LC(LA(LG(F3))) 
				&kp LC(LA(LG(F4))) 
				&kp LC(LA(LG(F5))) 
				&kp LC(ENTER)				// 

				// ----------------------------------------

				&turnOnMac
				&none
				&none
				&none
				&none
				&none

				&kp LC(LA(LG(F6))) 					
				&kp LC(LA(LG(F7))) 
				&kp LC(LA(LG(F8))) 
				&kp LC(LA(LG(F9))) 
				&kp LC(LA(LG(F10))) 
				&turnOnWin

				// ----------------------------------------
		
				&none
				&kp LG(SPACE)
				&mAlterShift				
				&mPNAVShift					
				&mNavShift					
				&mNrShift

				// ----------------------------------------
			>;
		};



		// -----------------------------------------------------|
		// Layer 19 - mSideShift =	Side Shift					|
		// -----------------------------------------------------|

		mac_mSSShift
		{
			label = "MAC";

			bindings = <

				// ----------------------------------------

				&kp ESC						// 
				&bt BT_SEL 0
				&bt BT_SEL 1
				&bt BT_SEL 2
				&bt BT_SEL 3
				&bt BT_CLR

				&kp LA(LG(F11)) 					
				&kp LA(LG(F12)) 
				&kp LA(LG(F13)) 
				&kp LA(LG(F14)) 
				&kp LA(LG(F15)) 
				&kp BACKSPACE				//

				// ----------------------------------------
		
				&mDeepShift
				&none	
				&none
				&none
				&kp LG(LA(LS(SPACE)))				
				&none

				&kp LA(LG(F1)) 					
				&kp LA(LG(F2)) 
				&kp LA(LG(F3)) 
				&kp LA(LG(F4)) 
				&kp LA(LG(F5)) 
				&kp LA(ENTER)				// 

				// ----------------------------------------

				&turnOnMac
				&none
				&none
				&none
				&none
				&none

				&kp LA(LG(F6)) 					
				&kp LA(LG(F7)) 
				&kp LA(LG(F8)) 
				&kp LA(LG(F9)) 
				&kp LA(LG(F10)) 
				&turnOnWin

				// ----------------------------------------
		
				&none
				&kp LG(LS(SPACE))
				&mAlterShift				
				&mPNAVShift					
				&mNavShift					
				&mNrShift

				// ----------------------------------------
			>;
		};






		// ----------------------------------------------------------------------------------------------|
		// 											WIN			
		// ----------------------------------------------------------------------------------------------|



		// -----------------------------------------------------|
		// Layer 0 - mChar = 	  Buchstaben					|
		// -----------------------------------------------------|
	
		win_buchstaben
		{
			label = "win";

			bindings = <

				// ----------------------------------------

				&kp ESC
				&kp J 
				&kp D	 
				&kp U
				&kp A
				&kp X

				&kp P
				&kp H
				&kp L
				&kp M
				&kp W
				&kp BSPC

				// ----------------------------------------
	
				&sl wSShift
				&kp C
				&kp T
				&kp I
				&kp E
				&kp O

				&kp B
				&kp N
				&kp R
				&kp S
				&kp G
				&kp RET

				// ----------------------------------------
	
				&mdLsWin
				&kp F
				&kp V
				&kp MINUS
				&kp Y
				&kp Q

				&kp Z
				&kp SEMI
				&kp LBKT
				&kp SQT
				&kp K
				&mdRsWin

				// ----------------------------------------

				&sl wSYM
				&kp SPACE
				&sl wFUNC
				&sl wPRG
				&sl wNAV
				&mdNrWin

				// ----------------------------------------
			>;
		};



		// -----------------------------------------------------|
		// Layer 1 - mNR = 	  Zahlen 							|
		// -----------------------------------------------------|

		win_zahlen
		{
			label = "win";

			bindings = <

				// ----------------------------------------

				&kp ESC	
				&kp RBKT  				// +
				&kp NUBS				// Spitze
				&kp LS(NUBS)			// Spitze
				&kp RA(N2)				// hoch 2
				&kp X
				
				&kp LS(NUHS)			// '
				&kp LS(DOT)				// :
				&kp LS(COMMA)			// ;
				&kp M
				&kp LS(RBKT)			// *				
				&kp BACKSPACE

				// ----------------------------------------

				&sl wSShift
				&kp N1				
				&kp N2				
				&kp N3				
				&kp N4					
				&kp N5		

				&kp N6				
				&kp N7				
				&kp N8			
				&kp N9				
				&kp N0				
				&wEnterReset 

				// ----------------------------------------

				&wShiftReset
				&kp LS(N7)				// /
				&kp LC(LA(MINUS))		// backlslash
				&kp LS(N5)				// %
				&kp LA(LC(E))			// €
				&kp GRAVE				// ^

				&kp LS(N0)				// =
				&kp DOT					// .
				&kp COMMA				// ,
				&kp LS(SLASH)			// _
				&kp SLASH 				// -
				&wShiftReset

				// ----------------------------------------
		
				&wSymReset
				&wSpaceReset 
				&wFuncReset
				&wPrgReset
				&wNavReset
				&none
			>;		
		};



		// -----------------------------------------------------|
		// Layer 2 - mLCHAR = 	  Buchstaben Lock				|
		// -----------------------------------------------------|
	
		win_lchar
		{
			label = "win";

			bindings = <

				// ----------------------------------------

				&kp ESC
				&kp LS(J) 
				&kp LS(D)	 
				&kp LS(U)
				&kp LS(A)
				&kp LS(X)

				&kp LS(P)
				&kp LS(H)
				&kp LS(L)
				&kp LS(M)
				&kp LS(W)
				&kp LS(BSPC)

				// ----------------------------------------
	
				&sl wSShift
				&kp LS(C)
				&kp LS(T)
				&kp LS(I)
				&kp LS(E)
				&kp LS(O)
			
				&kp LS(B)
				&kp LS(N)
				&kp LS(R)
				&kp LS(S)
				&kp LS(G)
				&wEnterReset

				// ----------------------------------------

				&wShiftReset
				&kp LS(F)
				&kp LS(V)
				&kp LS(MINUS)
				&kp LS(Y)
				&kp LS(Q)

				&kp LS(Z)
				&kp LS(SEMI)
				&kp LS(LBKT)
				&kp LS(SQT)
				&kp LS(K)
				&wShiftReset						

				// ----------------------------------------

				&sl mSYM
				&wSpaceReset 
				&wFuncReset
				&wPrgReset
				&wNavReset
				&mdNrWin

				// ----------------------------------------
			>;
		};



		// -----------------------------------------------------|
		// Layer 3 - mNRhard = 	  Zahlen Hard Lock				|
		// -----------------------------------------------------|

		win_zahlenhard
		{
			label = "win";

			bindings = <

				// ----------------------------------------

				&kp ESC	
				&kp RBKT  				// +
				&kp NUBS				// Spitze
				&kp LS(NUBS)			// Spitze
				&kp RA(N2)				// hoch 2
				&kp X
				
				&kp LS(NUHS)			// '
				&kp LS(DOT)				// :
				&kp LS(COMMA)			// ;
				&kp M
				&kp LS(RBKT)			// *	
				&kp BSPC

				// ----------------------------------------

				&sl wSShift
				&kp N1				
				&kp N2				
				&kp N3				
				&kp N4					
				&kp N5		

				&kp N6				
				&kp N7				
				&kp N8				
				&kp N9				
				&kp N0				
				&kp ENTER 

				// ----------------------------------------

				&wShiftReset
				&kp LS(N7)				// /
				&kp LC(LA(MINUS))		// backlslash
				&kp LS(N5)				// %
				&kp LA(LC(E))			// €
				&kp GRAVE				// ^

				&kp LS(N0)				// =
				&kp DOT					// .
				&kp COMMA				// ,
				&kp LS(SLASH)			// _
				&kp SLASH 				// -
				&wShiftReset

				// ----------------------------------------
		
				&sl wSYM
				&kp SPACE
				&sl wFUNC
				&sl wPRG
				&sl wNAV
				&none
			>;		
		};





		// -----------------------------------------------------|
		// Layer = 4 - wNAV - Navigation						|
		// -----------------------------------------------------|

		win_navigation
		{		
			label = "win";

			bindings = <

				// ----------------------------------------

				&kp ESC						// -
				&kp LC(HOME)				// @Home Sprung
				&kp LS(TAB)
				&kp UP						// @Up
				&kp TAB
				&kp LG(LA(F16))

				&kp LG(LA(F17))
				&kp LC(GRAVE)				
				&kp PG_UP
				&kp LC(EQUAL)		 	 
				&kp LC(LS(HOME))
				&kp BSPC					

				// ----------------------------------------

				&kp LC(COMMA)			 	// 
				&kp LC(END)					// @End Sprung
				&kp LEFT 					// @Left
				&kp DOWN					// @Down
				&kp RIGHT 					// @Right
				&kp LC(DOT)				 	// 

				&kp LC(LS(F10))
				&kp LS(LC(TAB))			 	// 
				&kp PG_DN
				&kp LC(TAB)				 	// 
				&kp LC(LS(END))
				&kp ENTER					// -
				
				// ----------------------------------------

				&kp LCTRL
				&kp HOME					// @Home 
				&kp LC(LEFT)				// @Wort Sprung
				&kp LC(RIGHT)				// @Wort Sprung
				&kp END
				&kp LG(LA(F18))

				&kp LG(LA(F19))
				&kp LS(HOME)					// @Home 
				&kp LS(LC(LEFT))				// @Wort Sprung
				&kp LS(LC(RIGHT))				// @Wort Sprung
				&kp LS(END)
				&kp LSHFT

				// ----------------------------------------

				&sl wSYM
				&kp SPACE				
				&sl wFUNC
				&sl wPRG
				&wReset
				&mdNrWin

				// ----------------------------------------							
			>;
		};




		// -----------------------------------------------------|
		// Layer 6 - mPRG =	Programme							|
		// -----------------------------------------------------|


		win_programme
		{
			label = "win";

			bindings = <

				// ----------------------------------------

				&kp LG(LS(F1))
				&kp LG(LS(N1))				// 11
				&kp LG(LS(N2))				// 12
				&kp LG(LS(N3))				// 13
				&kp LG(LS(N4))				// 14
				&kp LG(LS(N5))				// 15

				&kp LG(LS(N6))				// 16
				&kp LG(LS(N7))				// 17
				&kp LG(LS(N8))				// 18
				&kp LG(LS(N9))				// 19
				&kp LG(LS(N0))				// 20
				&kp LA(F4)

				// ----------------------------------------

				&kp LA(TAB)
				&kp LG(LA(LC(N1)))				// 1
				&kp LG(LA(LC(N2)))				// 2
				&kp LG(LA(LC(N3)))				// 3
				&kp LG(LA(LC(N4)))				// 4
				&kp LG(LA(LC(N5)))				// 5

				&kp LG(LA(LC(N6)))				// 6
				&kp LG(LA(LC(N7)))				// 7
				&kp LG(LA(LC(N8)))				// 8
				&kp LG(LA(LC(N9)))				// 9
				&kp LG(LA(LC(N0)))				// 0
				&kp LG(LS(F16))

				// ----------------------------------------

				&kp LG(LS(F2))
				&kp LS(LA(N1))			// 21 			
				&kp LS(LA(N2))			// 22
				&kp LS(LA(N3))			// 23
				&kp LS(LA(N4))			// 24
				&kp LS(LA(N5))			// 25
	
				&kp LS(LA(N6))			// 26
				&kp LS(LA(N7))			// 27
				&kp LS(LA(N8))			// 28
				&kp LS(LA(N9))			// 29
				&kp LS(LA(N0))			// 30
				&kp LG(LS(F3))
		
				// ----------------------------------------

				&none
				&none
				&none
				&sl wSPRG					// deep						
				&wNavShift
				&wCalc

				// ----------------------------------------

			>;
		};
		


		// -----------------------------------------------------|
		// Layer 7 - mSPRG =	Spezial Prgramme				|
		// -----------------------------------------------------|


		win_sprogramme
		{

			label = "win";

			bindings = <

				// ----------------------------------------

				&kp LG(D)				// Hide all
				&none
				&none
				&none
				&none
				&none

				&none
				&none
				&none
				&none
				&none
				&kp LC(LS(F10))			// Task Manager
		
				// ----------------------------------------

				&kp LG(TAB)				// #OPEN
				&kp LC(LG(N1))			//
				&kp LC(LG(N2))			//
				&kp LC(LG(N3))			//
				&kp LC(LG(N4))			//
				&kp LC(LG(N5))			//

				&kp LC(LG(N6))			//
				&kp LC(LG(N7))			//
				&kp LC(LG(N8))			//
				&kp LC(LG(N9))			//
				&kp LC(LG(N0))			//
				&kp LG(LS(F4))

				// ----------------------------------------

				&kp LG(LS(F5))
				&none
				&none
				&none
				&none
				&none

				&none
				&none
				&none
				&none
				&none
				&kp LG(LS(F6))
		
				// ----------------------------------------

				&none						//
				&none						//
				&none
				&trans						// 
				&wNavShift
				&none						// 

				// ----------------------------------------

			>;
		};
					


		// -----------------------------------------------------|
		// Layer 8 - mFUNC =	Funktionen						|
		// -----------------------------------------------------|

		win_function
		{
			label = "win";

			bindings = <

				// ----------------------------------------
	
				&kp LG(LS(F7))
				&kp LC(LA(F1))	
				&kp LC(LA(F2))	
				&kp LC(LA(F3))	
				&kp LC(LA(F4))	
				&kp LC(LA(F5))	

				&kp LC(LA(F6))	
				&kp LC(LA(F7))	
				&kp LC(LA(F8))	
				&kp LC(LA(F9))	
				&kp LC(LA(F10))	
				&kp LC(W)				
				
				// ----------------------------------------

				&kp LG(LS(F8))
				&kp LC(A)
				&kp LG(DEL)
				&kp LG(INSERT)	
				&kp LC(C)			
				&kp LC(X)

				&kp LG(V)
				&kp LC(V)
				&kp LC(LA(I))	
				&kp LC(LA(U))	
				&kp LC(LA(D))	
				&kp ENTER

				// ----------------------------------------

				&kp LG(LS(F9))
				&kp LC(S)
				&kp LC(Y)
				&kp LC(Z)
				&kp LC(O)
				&kp LC(D)	

				&kp LC(P)	
				&kp LC(LA(F))	
				&kp LC(LA(N))	
				&kp LC(LA(M))	
				&kp LC(F)	
				&kp LC(T)
				
				// ----------------------------------------

				&wModAltReset
				&sl wGUI					//
				&sl wSFUNC					// deep
				&none
				&wNavShift					//
				&none						//

				// ----------------------------------------
			>;
		};



		// -----------------------------------------------------|
		// Layer 9 - mSFUNC =	Spezial Funktionen				|
		// -----------------------------------------------------|

		win_specialfunction
		{
			label = "win";

			bindings = <

			// ----------------------------------------
	
				&kp LG(LS(F10))
				&kp LC(LA(LS(F1)))	
				&kp LC(LA(LS(F2)))	
				&kp LC(LA(LS(F3)))	
				&kp LC(LA(LS(F4)))	
				&kp LC(LA(LS(F5)))	

				&kp LC(LA(LS(F6)))	
				&kp LC(LA(LS(F7)))	
				&kp LC(LA(LS(F8)))	
				&kp LC(LA(LS(F9)))
				&kp LC(LA(LS(F10)))
				&kp LS(LC(W))
				
				// ----------------------------------------

				&kp LG(LS(F11))
				&kp LC(LS(A))
				&kp LG(LS(DEL))
				&kp LG(LS(INSERT))
				&kp LC(LS(C))			
				&kp LC(LS(X))

				&kp LG(LS(V))
				&kp LC(LS(V))
				&kp LC(LS(LA(I)))	
				&kp LC(LS(LA(U)))	
				&kp LC(LS(LA(D)))
				&kp LA(ENTER)	

				// ----------------------------------------

				&kp LG(LS(F12))
				&kp LC(LS(S))
				&kp LC(LS(Y))
				&kp LC(LS(Z))
				&kp LC(LS(O))
				&kp LC(LS(D))	 

				&kp LC(LS(P))
				&kp LC(LS(LA(F)))	
				&kp LC(LS(LA(N)))	
				&kp LC(LS(LA(M)))
				&kp LC(LS(F))
				&kp LC(LS(LS(T)))
				
				// ----------------------------------------

				&wModGuiReset
				&wModSCtlReset
				&trans						// 
				&none
				&wNavShift						//
				&none						//

				// ----------------------------------------       
			>;
		};



		// -----------------------------------------------------|
		// Layer 10 - mSYM =	Symoble							|
		// -----------------------------------------------------|

		win_symbole
		{
			label = "win";

			bindings = <

				// ----------------------------------------
				
				&kp ESC
				&kp RBKT  				// +
				&kp NUBS				// Spitze
				&kp LS(NUBS)			// Spitze
				&kp RA(N2)				// hoch 2
				&kp X
				
				&kp LS(NUHS)			// '
				&kp LS(DOT)				// :
				&kp LS(COMMA)			// ;
				&kp M
				&kp LS(RBKT)			// *	
				&kp BACKSPACE			// Backspace

				// ----------------------------------------

				&kp LCTL
				&kp RA(Q)				// @
				&kp LC(LA(NUBS))		// grader strich
				&kp LS(N6)				// &
				&kp NUHS				// #
				&kp LS(N3)				// §

				&kp LS(N2)				// "
				&kp LS(N1)				// !
				&kp LS(N8)				// Runde
				&kp LS(N9)				// Runde
				&kp LS(MINUS)			// ?
				&kp ENTER

				// ----------------------------------------

				&kp LSHIFT				//
				&kp LS(N7)				// /
				&kp LC(LA(MINUS))		// backlslash
				&kp LS(N5)				// %
				&kp LA(LC(E))			// €
				&kp GRAVE				// ^

				&kp LS(N0)				// =
				&kp DOT					// .
				&kp COMMA				// ,
				&kp LS(SLASH)			// _
				&kp SLASH 				// -
				&kp LG(DOT)   			// @Sonderzeichen
		
				// ----------------------------------------

				&sl wSSYM				// deep
				&none
				&none					// 
				&none					//
				&wNavShift					//
				&none					//

				// ----------------------------------------
			>;
		};


		// -----------------------------------------------------|
		// Layer 11 - mSSYM =	Special Symbole					|
		// -----------------------------------------------------|

		win_specialsonderzeichen
		{
			label = "win";

			bindings = <

				// ----------------------------------------

				&kp ESC
				&trans					//
				&trans 					// 
				&trans					//
				&kp RA(N3)				// hoch 3
				&trans					//

				&trans					//
				&trans
				&trans					//
				&kp RA(M)				// 
				&trans					//
				&kp BACKSPACE			// 

				// ----------------------------------------

				&kp LGUI
				&trans					//
				&kp LS(GRAVE)			// Grad
				&trans					//
				&trans					//
				&trans					//

				&trans					//
				&trans					//
				&kp RA(N8)				// Eckige
				&kp RA(N9)				// Eckige
				&trans					//
				&kp ENTER

				// ----------------------------------------

				&kp LALT
				&kp LS(LA(N7))			// 
				&trans
				&trans
				&kp LS(N4) 				// $
				&trans					//

				&kp LA(N)				// ~
				&trans
				&kp RA(N7)				// Geschweift
				&kp RA(N0)				// Geschweift
				&kp LS(SLASH)			// _
				&kp LG(DOT)   			// @Sonderzeichen

				// ----------------------------------------

				&trans					//
				&none
				&none					// 
				&none					//
				&wNavShift				// 
				&none					//

				// ----------------------------------------
			>;
		};	




		// -----------------------------------------------------|
		// Layer 12 - mGUI =	GUI								|
		// -----------------------------------------------------|

		win_gui
		{
			label = "win";

			bindings = <

				// ----------------------------------------

				&kp LC(ESC)					// 
				&kp LC(J)					//
				&kp LC(D)					//
				&kp LC(U)					//
				&kp LC(A)					//
				&kp LC(X)					//

				&kp LC(P)					//
				&kp LC(H)					//
				&kp LC(L) 					//
				&kp LC(M)					//
				&kp LC(W) 					//
				&kp LC(BACKSPACE)			//

				// ----------------------------------------
		
				&kp LC(DEL)					//
				&kp LC(C)					//
				&kp LC(T)					//
				&kp LC(I)					//
				&kp LC(E)					//
				&kp LC(O)					//

				&kp LC(B)					//
				&kp LC(N)					//
				&kp LC(R)					//
				&kp LC(S)					//
				&kp LC(G)					//
				&kp LC(ENTER)				// 

				// ----------------------------------------

				&kp LSHIFT
				&kp LC(F)					//
				&kp LC(V)					//
				&kp LC(MINUS)				//
				&kp LC(Y)					//
				&kp LC(Q)					//

				&kp LC(Z)					//
				&kp LC(SEMICOLON)			//
				&kp LC(LEFT_BRACKET)		//
				&kp LC(SINGLE_QUOTE)		//
				&kp LC(K) 					//
				&kp LSHIFT

				// ----------------------------------------
		
				&none						//
				&trans
				&none						// 
				&none						//
				&wNavShift						//
				&none						// 

				// ----------------------------------------
			>;
		};



		// -----------------------------------------------------|
		// Layer 16 - mAlter =	Alterantive						|
		// -----------------------------------------------------|

		win_mAlter
		{
			label = "win";

			bindings = <

				// ----------------------------------------

				&none
				&kp F1
				&kp F2
				&kp F3
				&kp F4
				&kp F5

				&kp F6
				&kp F7
				&kp F8
				&kp F9
				&kp F10
				&none

				// ----------------------------------------
		
				&none
				&kp LC(N1)					// 11
				&kp LC(N2)					// 12
				&kp LC(N3)					// 13
				&kp LC(N4)					// 14
				&kp LC(N5)					// 15

				&kp LC(N6)					// 16
				&kp LC(N7)					// 17
				&kp LC(N8)					// 18
				&kp LC(N9)					// 19
				&kp LC(N0)					// 20
				&none

				// ----------------------------------------

				&none
				&kp F11
				&kp F12
				&kp F13
				&kp F14
				&kp F15

				&kp LC(LS(F1))
				&kp LC(LS(F2))
				&kp LC(LS(F3))
				&kp LC(LS(F4))
				&kp LC(LS(F5))
				&none

				// ----------------------------------------
		
				&none						//
				&trans
				&none						// 
				&none						//
				&wNavShift						//
				&none						// 

				// ----------------------------------------
			>;
		};






		// -----------------------------------------------------|
		// Layer 17 - mPNAV =	Programm NAV					|
		// -----------------------------------------------------|

		win_pnav
		{
			label = "win";

			bindings = <

				// ----------------------------------------

				&kp LC(LA(ENTER))				//
				&none						//
				&kp LC(LA(LS(LEFT)))		// 
				&kp LC(LA(UP))				// 
				&kp LC(LA(LS(RIGHT)))		// 
				&none						// 

				&kp LA(LG(F11)) 					
				&kp LA(LG(F12))					
				&kp LA(LG(F13)) 					
				&kp LA(LG(F14))					
				&kp LA(LG(F15)) 
				&kp BACKSPACE				//

				// ----------------------------------------
		
				&none						//
				&none						//
				&kp LC(LA(LEFT))			// 
				&kp LC(LA(DOWN))			// 
				&kp LC(LA(RIGHT))			// 
				&none						// 

				&kp LA(LG(F1)) 					
				&kp LA(LG(F2))					
				&kp LA(LG(F3))					
				&kp LA(LG(F4)) 					
				&kp LA(LG(F5)) 	
				&none						//

				// ----------------------------------------

				&none						//
				&none						//
				&none						// 
				&none						//
				&none						// 
				&none						// 

				&kp LA(LG(F6)) 					
				&kp LA(LG(F7))					
				&kp LA(LG(F8)) 					
				&kp LA(LG(F9))					
				&kp LA(LG(F10)) 
				&none						//

				// ----------------------------------------
		
				&none						//
				&none
				&none						// 
				&none						//
				&wNavShift
				&none						// 

				// ----------------------------------------
			>;
		};




		// -----------------------------------------------------|
		// Layer 19 - mSideShift =	Side Shift					|
		// -----------------------------------------------------|

		win_mSShift
		{
			label = "win";

			bindings = <

				// ----------------------------------------

				&kp ESC						// 
				&bt BT_SEL 0
				&bt BT_SEL 1
				&bt BT_SEL 2
				&bt BT_SEL 3
				&bt BT_CLR

				&kp LA(LG(LC(F11))) 					
				&kp LA(LG(LC(F12))) 					
				&kp LA(LG(LC(F13))) 					
				&kp LA(LG(LC(F14))) 					
				&kp LA(LG(LC(F15)))  					
				&kp BACKSPACE				//

				// ----------------------------------------
		
				&wDeepShift
				&none
				&none
				&none
				&wAltShot
				&none

				&kp LA(LG(LC(F1))) 					
				&kp LA(LG(LC(F2))) 					
				&kp LA(LG(LC(F3))) 					
				&kp LA(LG(LC(F4))) 					
				&kp LA(LG(LC(F5))) 					
				&kp LC(ENTER)				// 

				// ----------------------------------------

				&turnOnMac
				&none
				&none
				&none
				&none
				&none

				&kp LA(LG(LC(F6))) 					
				&kp LA(LG(LC(F7))) 					
				&kp LA(LG(LC(F8))) 					
				&kp LA(LG(LC(F9))) 					
				&kp LA(LG(LC(F10))) 					 					
				&turnOnWin

				// ----------------------------------------
		
				&none
				&kp LG(S)
				&wAlterShift				// 
				&wPNAVShift					//
				&wNavShift					//
				&wNrShift

				// ----------------------------------------
			>;
		};


		// -----------------------------------------------------|
		// Layer 19 - mSideShift =	Side Shift					|
		// -----------------------------------------------------|

		win_mSSShift
		{
			label = "win";

			bindings = <

				// ----------------------------------------

				&kp ESC						// 
				&bt BT_SEL 0
				&bt BT_SEL 1
				&bt BT_SEL 2
				&bt BT_SEL 3
				&bt BT_CLR

				&kp LA(LG(F11)) 					
				&kp LA(LG(F12)) 					
				&kp LA(LG(F13)) 					
				&kp LA(LG(F14)) 					
				&kp LA(LG(F15))  					
				&kp BACKSPACE				//

				// ----------------------------------------
		
				&wDeepShift
				&none
				&none
				&none
				&wAltShot
				&none

				&kp LA(LG(F1)) 					
				&kp LA(LG(F2)) 					
				&kp LA(LG(F3))					
				&kp LA(LG(F4)) 					
				&kp LA(LG(F5)) 					
				&kp LA(ENTER)				// 

				// ----------------------------------------

				&turnOnMac
				&none
				&none
				&none
				&none
				&none

				&kp LA(LG(F6)) 					
				&kp LA(LG(F7)) 					
				&kp LA(LG(F8)) 					
				&kp LA(LG(F9)) 					
				&kp LA(LG(F10)) 					 					
				&turnOnWin

				// ----------------------------------------
		
				&none
				&kp LG(LS(S))
				&wAlterShift				// 
				&wPNAVShift					//
				&wNavShift					//
				&wNrShift

				// ----------------------------------------
			>;
		};



		
	};
};

